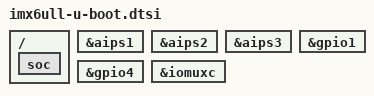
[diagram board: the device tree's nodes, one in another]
// SPDX-License-Identifier: GPL-2.0+
/*
 * Copyright (C) 2019 Parthiban Nallathambi <parthitce@gmail.com>
 */

/ {
	soc {
		u-boot,dm-spl;
	};
};

&aips1 {
	u-boot,dm-spl;
};

&aips2 {
	u-boot,dm-spl;
};

&aips3 {
	u-boot,dm-spl;
};

&gpio1 {
	u-boot,dm-spl;
};

&gpio4 {
	u-boot,dm-spl;
};

&iomuxc {
	u-boot,dm-spl;
};
